# DSS_EDP0_V2A_CORE_VP_REGS_APB register map
Vendor: Texas Instruments
Peripheral module from a debugger description file (folder J721S2).
Registers are 32-bit, access not given, reset 0x0 unless marked. A register's access mark holds for its fields unless they carry their own. Offsets are as the file gives them; lines under a group give offsets from that group; [hi:lo] are bit positions; {n}, {i} and the like mark numbered series; 'fields as' and 'values as' point back to an identical list; <NAME> marks a mode.

## DSS_EDP0_V2A_CORE_VP_REGS_APB (part 1 of 4)
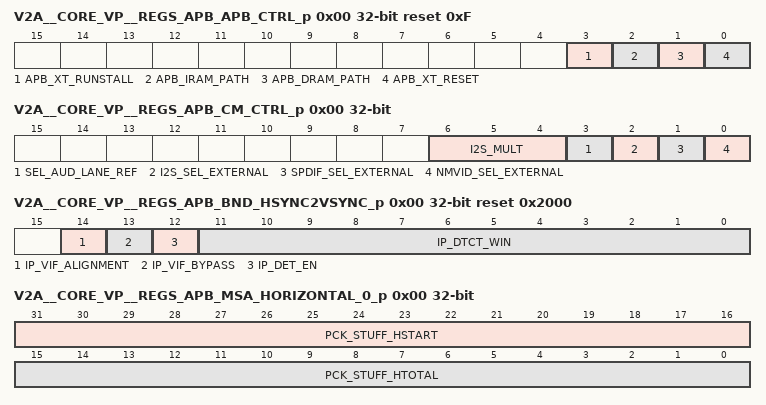
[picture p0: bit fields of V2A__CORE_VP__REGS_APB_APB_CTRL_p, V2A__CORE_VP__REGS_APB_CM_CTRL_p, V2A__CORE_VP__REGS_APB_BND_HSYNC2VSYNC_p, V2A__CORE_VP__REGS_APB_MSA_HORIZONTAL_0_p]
0x00 V2A__CORE_VP__REGS_APB_APB_CTRL_p reset 0xF — APB main control register
  [3] APB_XT_RUNSTALL rw — When 1 stalls the CPU from executing further instructions. This bit must be set HIGH during firmware load.
  [2] APB_IRAM_PATH rw — Unused. Kept RW for software backward compatibility.
  [1] APB_DRAM_PATH rw — Unused. Kept RW for software backward compatibility.
  [0] APB_XT_RESET rw — Internal uCPU reset. Active High. Must be cleared to enable firmware load and normal operation of the uCPU.
0x00 V2A__CORE_VP__REGS_APB_CM_CTRL_p — Clock Meter control
  [6:4] I2S_MULT rw — Select the division of N value for different I2S TDM configuration
  [3] SEL_AUD_LANE_REF rw — When 1 Select Audio CLK as a reference [HDMI] When 0 Select LANE CLK as a reference [DP]
  [2] I2S_SEL_EXTERNAL rw — When 1 Select external values of NMAUD [N/A] for I2S
  [1] SPDIF_SEL_EXTERNAL rw — When 1 Select external values of NMAUD [N/A] for SPDIF
  [0] NMVID_SEL_EXTERNAL rw — When 1 Select external values of NMVID [N/A]
0x00 V2A__CORE_VP__REGS_APB_CM_CTRL_p — Clock Meter control
  fields as V2A__CORE_VP__REGS_APB_CM_CTRL_p
0x00 V2A__CORE_VP__REGS_APB_BND_HSYNC2VSYNC_p reset 0x2000 — Video Input Interface Setting Register
  [14] IP_VIF_ALIGNMENT rw — Alignment of the input pixel data at the pixel interface: 0-MSB alignment 1-LSB alignment.
  [13] IP_VIF_BYPASS rw — Bypass video interface.
  [12] IP_DET_EN rw — Enable detection of Interlace formats after decided if the polarity is Automatic or Manual detection.
  [11:0] IP_DTCT_WIN rw — Bound for HSYNC to VSYNC for all fields.
0x00 V2A__CORE_VP__REGS_APB_MSA_HORIZONTAL_0_p rw — MSA horizontal parameters. This settings define MSA content (not used for input video stream parameters). This field must be set prior video is enabled and must not be changed when video transmission is active.
  [31:16] PCK_STUFF_HSTART — MSA Hstart value. Horizontal active start from leading edge of Hsync, measured in pixel count.
  [15:0] PCK_STUFF_HTOTAL — MSA HTotal value. Horizontal total of transmitted main video stream, measured in pixel count.
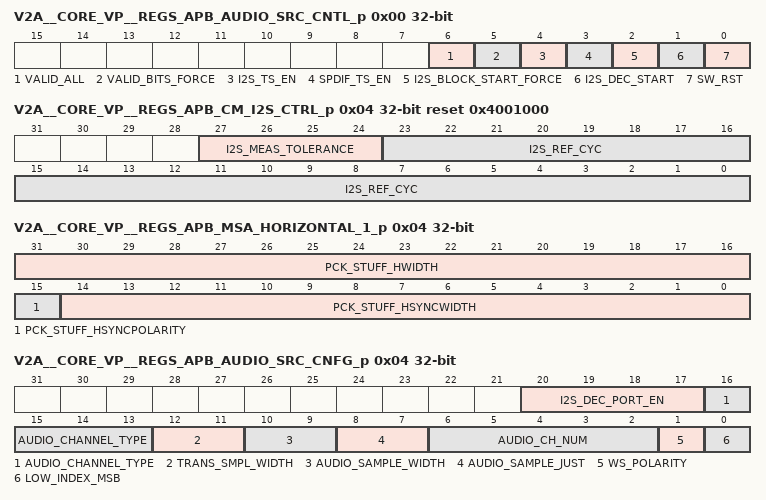
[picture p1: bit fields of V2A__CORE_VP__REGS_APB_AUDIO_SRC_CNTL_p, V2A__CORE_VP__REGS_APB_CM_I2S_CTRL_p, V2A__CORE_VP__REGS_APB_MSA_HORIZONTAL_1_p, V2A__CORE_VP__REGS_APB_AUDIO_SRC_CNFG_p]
0x00 V2A__CORE_VP__REGS_APB_AUDIO_SRC_CNTL_p — Audio source control
  [6] VALID_ALL rw — valid bit for all samples
  [5] VALID_BITS_FORCE rw — Force valid bits of the channels
  [4] I2S_TS_EN rw — Enable I2S Time Stamp when decoders are disabled
  [3] SPDIF_TS_EN rw — Enable SPDIF Time Stamp when decoders are disabled
  [2] I2S_BLOCK_START_FORCE rw — Force a Block Start in the audio stream
  [1] I2S_DEC_START rw — When high Source Decoder starts.
  [0] SW_RST rw — Software reset. Active high.
0x00 V2A__CORE_VP__REGS_APB_SOURCE_PIF_WR_ADDR_p — 4 MSB of the packet memory address in which the data is written.
  [3:0] WR_ADDR rw
0x04 V2A__CORE_VP__REGS_APB_xt_int_ctrl_p — Inernal CPU Interrupt Polarity Control Register.
  [1:0] XT_INT_POLARITY rw — Each bit inverts appropriate interrupt signal provided do internal CPU interrupt input.
0x04 V2A__CORE_VP__REGS_APB_CM_I2S_CTRL_p reset 0x4001000 — I2S clock control
  [27:24] I2S_MEAS_TOLERANCE rw — Measurement tolerance of Audio clock to be stable in clocks
  [23:0] I2S_REF_CYC rw — Reference cycles for I2S Audio meter
0x04 V2A__CORE_VP__REGS_APB_HSYNC2VSYNC_F1_L1_p — Status of HSYNC to VSYNC Distance Counter 1.
  [15:0] IP_DTCT_HSYNC2VSYNC_F1 ro — Value of HSYNC to VSYNC field 1.
0x04 V2A__CORE_VP__REGS_APB_MSA_HORIZONTAL_1_p rw — MSA horizontal parameters. This settings define MSA content (not used for input video stream parameters). This field must be set prior video is enabled and must not be changed when video transmission is active.
  [31:16] PCK_STUFF_HWIDTH — MSA Hwidth parameter. Active video width, measured in pixel count.
  [15] PCK_STUFF_HSYNCPOLARITY — MSA HSync Polarity. 0 - Active high pulse. Synchronization signal is high for the sync pulse width. 1 - Active low pulse. Synchronization signal is low for the sync pulse width. This value may be different than actual polarity of the stream received at the video input interface.
  [14:0] PCK_STUFF_HSYNCWIDTH — MSA HSyncWidth parameter. Hsync width, measured in pixel count.
0x04 V2A__CORE_VP__REGS_APB_AUDIO_SRC_CNFG_p — Audio source configuration
  [20:17] I2S_DEC_PORT_EN rw — Enables the I2S Decoder ports. Allowed values are: 0001 - I2S port 0 is enabled. 0011 - I2S ports 0,1 are enabled. 1111 - I2S ports 0,1,2,3 are enabled. No other values are allowed.
  [16:13] AUDIO_CHANNEL_TYPE rw — Set the transmission type.
  [12:11] TRANS_SMPL_WIDTH rw — Decoder Word Select width: 00-16 bit 01-24 bit 10-32 bit
  [10:9] AUDIO_SAMPLE_WIDTH rw — Decoder sample width: 00-16 bit 01-24 bit 10-32 bit
  [8:7] AUDIO_SAMPLE_JUST rw — Data justification setting: 00 left-justified 01 right-justified
  [6:2] AUDIO_CH_NUM rw — Number of channels to decode
  [1] WS_POLARITY rw — Word Select Polarity. 0: No change 1: Inverted.
  [0] LOW_INDEX_MSB rw — When low MSB is transmitted first. When high LSB is transmitted first.
0x04 V2A__CORE_VP__REGS_APB_SOURCE_PIF_WR_REQ_p — Write request bit for the host write transaction.
  [0] HOST_WR rw — Write request bit for the host write transaction, active high. Bit is automatically cleared when operation is completed.
0x08 V2A__CORE_VP__REGS_APB_MAILBOX_FULL_ADDR_p — Mailbox full indication status register. This register provides a status of the mailbox that is used to send messages from the Host processor to internal uCPU. Mailbox full flag can be a source of mailbox interrupt.
  [0] MAILBOX_FULL ro — Mailbox full indication. 0x1-mailbox full. No more messages can be sent to mailbox 0x0-mailbox not-full. At least 1 write can be performed to mailbox
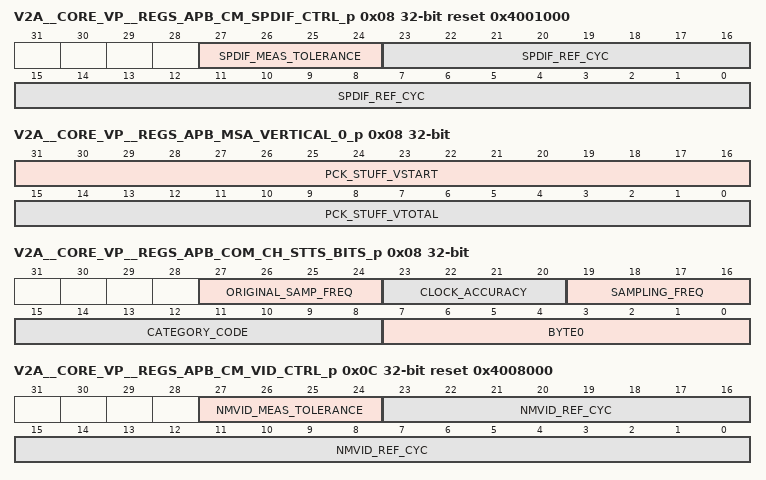
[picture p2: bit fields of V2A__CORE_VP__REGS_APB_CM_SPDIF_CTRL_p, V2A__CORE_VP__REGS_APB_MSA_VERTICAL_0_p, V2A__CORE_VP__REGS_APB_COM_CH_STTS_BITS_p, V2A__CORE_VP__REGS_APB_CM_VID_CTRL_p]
0x08 V2A__CORE_VP__REGS_APB_CM_SPDIF_CTRL_p reset 0x4001000 — SPDIF clock control
  [27:24] SPDIF_MEAS_TOLERANCE rw — SPDIF measurement tolerance to be stable in clocks
  [23:0] SPDIF_REF_CYC rw — Reference cycles of SPDIF measurement
0x08 V2A__CORE_VP__REGS_APB_HSYNC2VSYNC_F2_L1_p — Status of HSYNC to VSYNC Distance Counter 2
  [15:0] IP_DTCT_HSYNC2VSYNC_F2 ro — Value of HSYNC to VSYNC field 2.
0x08 V2A__CORE_VP__REGS_APB_MSA_VERTICAL_0_p rw — MSA vertical parameters. This settings define MSA content (not used for input video stream parameters). This field must be set prior video is enabled and must not be changed when video transmission is active.
  [31:16] PCK_STUFF_VSTART — MSA Vstart parameter. Vertical active start from leading edge of Vsync, measured in line count.
  [15:0] PCK_STUFF_VTOTAL — MSA Vtotal parameter. Vertical total of transmitted main video stream, measured in line count.
0x08 V2A__CORE_VP__REGS_APB_COM_CH_STTS_BITS_p — Common channels configuration
  [27:24] ORIGINAL_SAMP_FREQ rw — Original Sampling Freq. of transmitted channel. Same for all channels.
  [23:20] CLOCK_ACCURACY rw — Clock Accuracy of transmitted channel. Same for all channels.
  [19:16] SAMPLING_FREQ rw — Sampling Frequency of transmitted channel. Same for all channels.
  [15:8] CATEGORY_CODE rw — Category Code of transmitted channel. Same for all channels.
  [7:0] BYTE0 rw — Byte 0 of transmitted channel. Same for all channels.
0x08 V2A__CORE_VP__REGS_APB_SOURCE_PIF_RD_ADDR_p — 4 MSB of the packet memory address from which the data is read.
  [3:0] RD_ADDR rw
0x0C V2A__CORE_VP__REGS_APB_MAILBOX_EMPTY_ADDR_p reset 0x1 — Mailbox empty indication status register. This register provides a status of the mailbox that is used to send responses from the internal uCPU to host processor as a result of previously sent message. Mailbox empty flag can be a source of not-empty mailbox interrupt.
  [0] MAILBOX_EMPTY ro — Mailbox empty indication. 0x1-mailbox empty. No response available 0x0-mailbox not-empty. There is at least 1 byte of a response in mailbox available to read by Host processor
0x0C V2A__CORE_VP__REGS_APB_CM_VID_CTRL_p reset 0x4008000 — Video clock control
  [27:24] NMVID_MEAS_TOLERANCE rw — Video measurement tolerance in pixel clock cycles
  [23:0] NMVID_REF_CYC rw — Video Reference cycles
0x0C V2A__CORE_VP__REGS_APB_CM_VID_CTRL_p reset 0x4008000 — Video clock control
  fields as V2A__CORE_VP__REGS_APB_CM_VID_CTRL_p
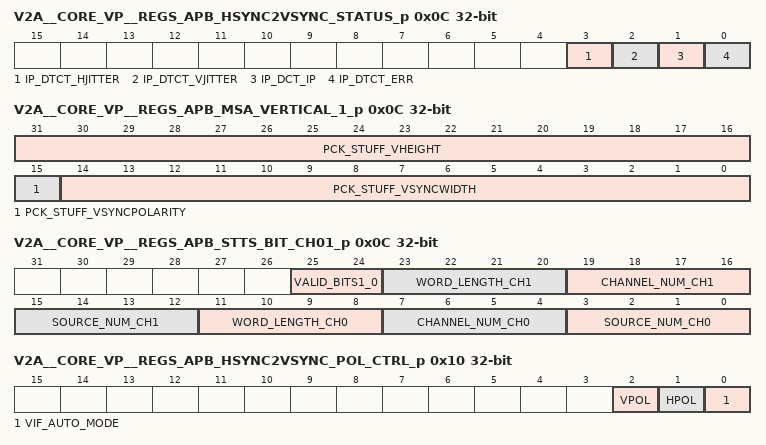
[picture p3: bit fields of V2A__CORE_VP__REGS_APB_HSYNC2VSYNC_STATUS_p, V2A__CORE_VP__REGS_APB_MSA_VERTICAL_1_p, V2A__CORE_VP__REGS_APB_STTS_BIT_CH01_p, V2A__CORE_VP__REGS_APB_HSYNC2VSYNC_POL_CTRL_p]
0x0C V2A__CORE_VP__REGS_APB_HSYNC2VSYNC_STATUS_p — Video Interface Status Register
  [3] IP_DTCT_HJITTER ro — Asserted when jitter is observed on htotal i.e. HSYNC rising edge to next HSYNC rising edge delay count. Clear on Read.
  [2] IP_DTCT_VJITTER ro — Asserted when jitter is observed on vtotal i.e. VSYNC rising edge to next VSYNC rising edge delay count. Clear on Read.
  [1] IP_DCT_IP ro — When asserted interlaced format is detected else progressive format.
  [0] IP_DTCT_ERR ro — Asserted when HSYNC to VSYNC bound is violated. Clear on Read.
0x0C V2A__CORE_VP__REGS_APB_MSA_VERTICAL_1_p rw — MSA vertical parameters. This settings define MSA content (not used for input video stream parameters). This field must be set prior video is enabled and must not be changed when video transmission is active.
  [31:16] PCK_STUFF_VHEIGHT — MSA VHeigh parameter. Active video height, measured in line count.
  [15] PCK_STUFF_VSYNCPOLARITY — MSA VSyncPolarity. 0 - Active high pulse. Synchronization signal is high for the sync pulse width. 1 - Active low pulse. Synchronization signal is low for the sync pulse width. This value may be different than actual polarity of the stream received at the video input interface.
  [14:0] PCK_STUFF_VSYNCWIDTH — MSA VSyncWidth parameter. Vsync width, measured in line count.
0x0C V2A__CORE_VP__REGS_APB_STTS_BIT_CH01_p — Channels 0,1 configuration
  [25:24] VALID_BITS1_0 rw — Valid Bits for channel 1 and 0 if force is enabled
  [23:20] WORD_LENGTH_CH1 rw — Channel 1 word length.
  [19:16] CHANNEL_NUM_CH1 rw — Channel 1 channel number.
  [15:12] SOURCE_NUM_CH1 rw — Channel 1 Source number.
  [11:8] WORD_LENGTH_CH0 rw — Channel 0 word length.
  [7:4] CHANNEL_NUM_CH0 rw — Channel 0 channel number.
  [3:0] SOURCE_NUM_CH0 rw — Channel 0 Source number.
0x0C V2A__CORE_VP__REGS_APB_SOURCE_PIF_RD_REQ_p — Read request bit for the host read transaction.
  [0] HOST_RD rw — Read request bit for the host read transaction, active high. Bit is automatically cleared when operation is completed.
0x10 V2A__CORE_VP__REGS_APB_mailbox0_wr_data_p — Mailbox write data register.
  [7:0] MAILBOX0_WR_DATA rw — Mailbox write data.
0x10 V2A__CORE_VP__REGS_APB_CM_LANE_CTRL_p — Lane control
  [23:0] LANE_REF_CYC rw — Reference cycles when using lane clock as Reference [DP]
0x10 V2A__CORE_VP__REGS_APB_HSYNC2VSYNC_POL_CTRL_p — Setting Polarity of HSYNC and VSYNC
  [2] VPOL rw — VSYNC polarity: 0-active HIGH 1-active LOW.
  [1] HPOL rw — HSYNC polarity: 0-active HIGH 1-active LOW.
  [0] VIF_AUTO_MODE rw — Automatic or Manual configuration of the polarity: 0-vpol and hpol settings are used 1-automatic detection of polarity of input VSYNC and HSYNC
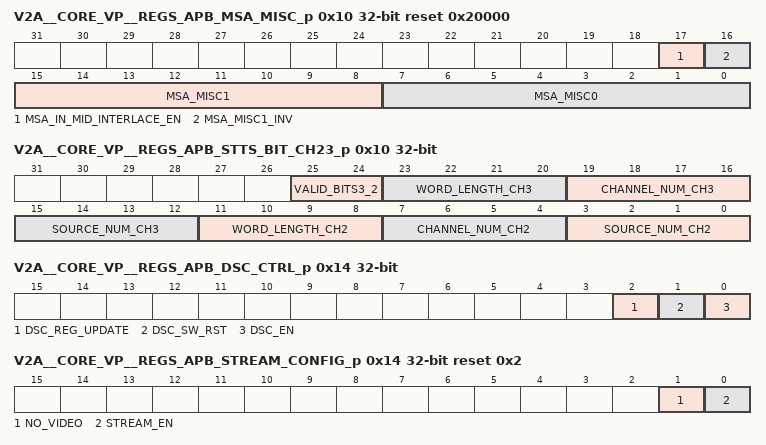
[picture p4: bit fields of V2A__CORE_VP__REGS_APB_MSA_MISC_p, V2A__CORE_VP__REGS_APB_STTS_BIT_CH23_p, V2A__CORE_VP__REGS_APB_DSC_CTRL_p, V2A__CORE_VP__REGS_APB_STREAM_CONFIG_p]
0x10 V2A__CORE_VP__REGS_APB_MSA_MISC_p reset 0x20000 — MSA MISC0 and MISC1 control register. This field must be set prior video is enabled and must not be changed when video transmission is active.
  [17] MSA_IN_MID_INTERLACE_EN rw — MSA transmission control in interlaced mode. 0 - enable transmission of MSA on each field, 1 - MSA transmitted on Top only
  [16] MSA_MISC1_INV rw — L/R toggle for interlaced and field sequential video. 0 - left 1 - right
  [15:8] MSA_MISC1 rw — MAS Miscellaneous1 as described in DisplayPort specification.
  [7:0] MSA_MISC0 rw — MSA Miscellaneous0 as described in DisplayPort specification.
0x10 V2A__CORE_VP__REGS_APB_STTS_BIT_CH23_p — Channels 2,3 configuration
  [25:24] VALID_BITS3_2 rw — Valid Bits for channel 3 and 2 if force is enabled
  [23:20] WORD_LENGTH_CH3 rw — Channel 3 word length.
  [19:16] CHANNEL_NUM_CH3 rw — Channel 3 channel number.
  [15:12] SOURCE_NUM_CH3 rw — Channel 3 Source number.
  [11:8] WORD_LENGTH_CH2 rw — Channel 2 word length.
  [7:4] CHANNEL_NUM_CH2 rw — Channel 2 channel number.
  [3:0] SOURCE_NUM_CH2 rw — Channel 2 Source number.
0x10 V2A__CORE_VP__REGS_APB_SOURCE_PIF_DATA_WR_p rw — The 32 bits of the data to be written to the packet memory.
  [31:0] DATA_WR — The 32 bits of the data to be written to the packet memory. When written to this register fifo1_wr_enable will automatically be asserted and the data is stored in FIFO.
0x14 V2A__CORE_VP__REGS_APB_mailbox0_rd_data_p — Mailbox Read data register.
  [7:0] MAILBOX0_RD_DATA ro — Mailbox Read data.
0x14 V2A__CORE_VP__REGS_APB_I2S_NM_STABLE_p — I2S clock stable, audio clock measured
  [0] I2S_MNAUD_STABLE ro — I2S NMAUD Mesurment stable
0x14 V2A__CORE_VP__REGS_APB_DSC_CTRL_p — DSC Setting Register
  [2] DSC_REG_UPDATE rw — DSC registers update: active HIGH.
  [1] DSC_SW_RST rw — DSC software reset: active HIGH.
  [0] DSC_EN rw — DSC enable bit: 1-DSC is enabled 0-DSC is disabled
0x14 V2A__CORE_VP__REGS_APB_STREAM_CONFIG_p reset 0x2 — Stream configuration register. Used only in MST mode.
  [1] NO_VIDEO rw — Stream no video mode. 0 - video mode 1 - no video mode
  [0] STREAM_EN rw — Stream enable. 0 - stream disabled 1 - stream enabled
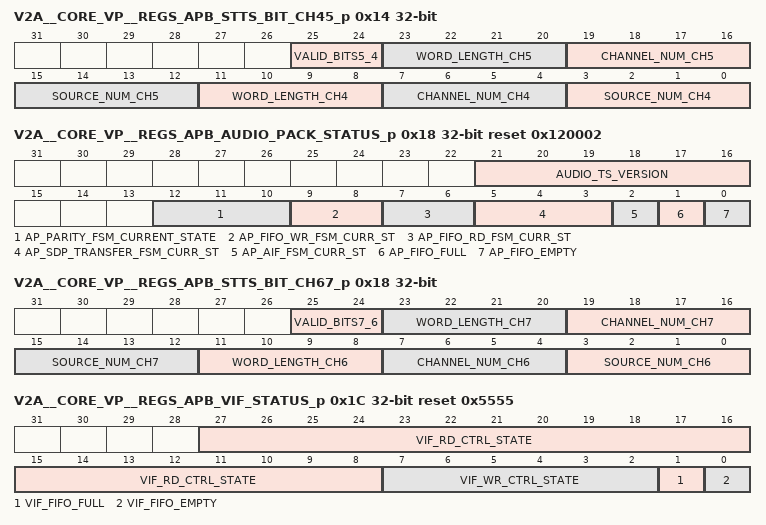
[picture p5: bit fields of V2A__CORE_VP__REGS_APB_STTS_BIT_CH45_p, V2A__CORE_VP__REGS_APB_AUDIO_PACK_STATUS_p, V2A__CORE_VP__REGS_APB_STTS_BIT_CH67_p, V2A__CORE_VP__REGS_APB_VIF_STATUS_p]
0x14 V2A__CORE_VP__REGS_APB_STTS_BIT_CH45_p — Channels 4,5 configuration
  [25:24] VALID_BITS5_4 rw — Valid Bits for channel 5 and 4 if force is enabled
  [23:20] WORD_LENGTH_CH5 rw — Channel 5 word length.
  [19:16] CHANNEL_NUM_CH5 rw — Channel 5 channel number.
  [15:12] SOURCE_NUM_CH5 rw — Channel 5 Source number.
  [11:8] WORD_LENGTH_CH4 rw — Channel 4 word length.
  [7:4] CHANNEL_NUM_CH4 rw — Channel 4 channel number.
  [3:0] SOURCE_NUM_CH4 rw — Channel 4 Source number.
0x14 V2A__CORE_VP__REGS_APB_SOURCE_PIF_DATA_RD_p ro — The 32 bits of the data to be read from the packet memory.
  [31:0] FIFO2_DATA_OUT — The 32 bits of the data to be read from the packet memory. When read from this register fifo2_rd_enable will automatically be asserted and the data is read from the FIFO.
0x18 V2A__CORE_VP__REGS_APB_KEEP_ALIVE_p — Software keep alive counter.
  [7:0] KEEP_ALIVE_CNT ro — Software keep alive counter. Counter is initialized to 0x0 after reset and incremented by 0x1 with every FW kernel loop. It can be used to determine if internal CPU started running correctly.
0x18 V2A__CORE_VP__REGS_APB_I2S_NCTS_STABLE_p — I2S clock stable, lane clock measured
  [0] I2S_NCTS_STABLE ro — i2s CTS measurement stable
0x18 V2A__CORE_VP__REGS_APB_AUDIO_PACK_STATUS_p reset 0x120002 — Status signals for the audio pack.
  [21:16] AUDIO_TS_VERSION rw — Audio timestamp version. This field is transmitted in HB3[7:2] of a Audio_TimeStamp SDP Header.
  [12:10] AP_PARITY_FSM_CURRENT_STATE ro — Audio pack parity calc fsm state. Used only for debug purposes.
  [9:8] AP_FIFO_WR_FSM_CURR_ST ro — Audio pack FIFO write fsm state. Used only for debug purposes.
  [7:6] AP_FIFO_RD_FSM_CURR_ST ro — Audio pack FIFO read fsm state. Used only for debug purposes.
  [5:3] AP_SDP_TRANSFER_FSM_CURR_ST ro — Audio pack sdp transfer fsm state. Used only for debug purposes.
  [2] AP_AIF_FSM_CURR_ST ro — Audio pack aif fsm state. Used only for debug purposes.
  [1] AP_FIFO_FULL ro — Audio Pack Sync FIFO full flag, active high. Used only for debug purposes.
  [0] AP_FIFO_EMPTY ro — Audio Pack Sync FIFO empty flag, active high. Used only for debug purposes.
0x18 V2A__CORE_VP__REGS_APB_STTS_BIT_CH67_p — Channels 6,7 configuration
  [25:24] VALID_BITS7_6 rw — Valid Bits for channel 7 and 6 if force is enabled
  [23:20] WORD_LENGTH_CH7 rw — Channel 7 word length.
  [19:16] CHANNEL_NUM_CH7 rw — Channel 7 channel number.
  [15:12] SOURCE_NUM_CH7 rw — Channel 7 Source number.
  [11:8] WORD_LENGTH_CH6 rw — Channel 6 word length.
  [7:4] CHANNEL_NUM_CH6 rw — Channel 6 channel number.
  [3:0] SOURCE_NUM_CH6 rw — Channel 6 Source number.
0x18 V2A__CORE_VP__REGS_APB_SOURCE_PIF_FIFO1_FLUSH_p — Fifo1 flush
  [0] FIFO1_FLUSH rw — Fifo1 flush bit, active high. Bit is automatically cleared when operation is completed.
0x1C V2A__CORE_VP__REGS_APB_VER_L_p — Software Version Register.
  [7:0] VER_LSB ro — Software Version lower byte. Loaded by Firmware at the beginning of firmware operation.
0x1C V2A__CORE_VP__REGS_APB_SPDIF_NM_STABLE_p — SPDIF clock stable, audio clock measured
  [0] SPDIF_MNAUD_STABLE ro — SPDIF NMAUD measurement stable
0x1C V2A__CORE_VP__REGS_APB_VIF_STATUS_p reset 0x5555 — Status signals for the VIF module. Used only for debug purposes.
  [27:8] VIF_RD_CTRL_STATE ro — VIF rd fsm current state.
  [7:2] VIF_WR_CTRL_STATE ro — VIF wr fsm current state.
  [1] VIF_FIFO_FULL ro — VIF ASync FIFO full flag, active high.
  [0] VIF_FIFO_EMPTY ro — VIF ASync FIFO empty flag, active high.
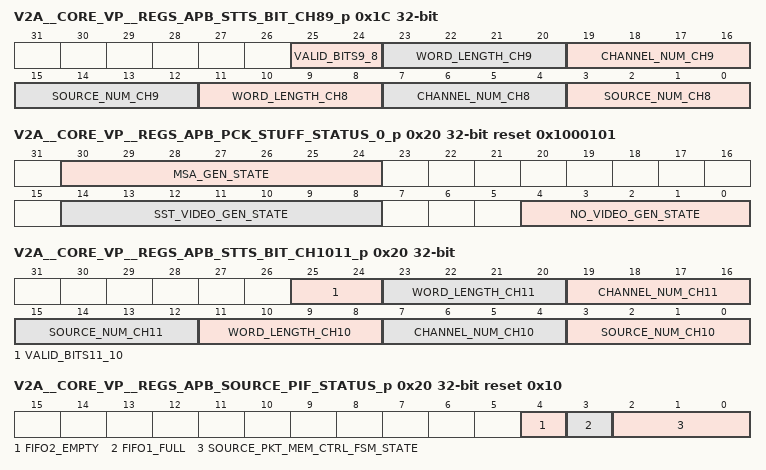
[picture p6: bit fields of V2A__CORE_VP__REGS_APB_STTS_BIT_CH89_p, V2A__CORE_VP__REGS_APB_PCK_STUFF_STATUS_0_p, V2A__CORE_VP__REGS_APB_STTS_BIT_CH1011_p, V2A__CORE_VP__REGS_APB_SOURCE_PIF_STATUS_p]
0x1C V2A__CORE_VP__REGS_APB_STTS_BIT_CH89_p — Channels 8,9 configuration
  [25:24] VALID_BITS9_8 rw — Valid Bits for channel 9 and 8 if force is enabled
  [23:20] WORD_LENGTH_CH9 rw — Channel 9 word length.
  [19:16] CHANNEL_NUM_CH9 rw — Channel 9 channel number.
  [15:12] SOURCE_NUM_CH9 rw — Channel 9 Source number.
  [11:8] WORD_LENGTH_CH8 rw — Channel 8 word length.
  [7:4] CHANNEL_NUM_CH8 rw — Channel 8 channel number.
  [3:0] SOURCE_NUM_CH8 rw — Channel 8 Source number.
0x1C V2A__CORE_VP__REGS_APB_SOURCE_PIF_FIFO2_FLUSH_p — Fifo2 flush
  [0] FIFO2_FLUSH rw — Fifo2 flush bit, active high. Bit is automatically cleared when operation is completed.
0x20 V2A__CORE_VP__REGS_APB_VER_H_p — Software Version Register.
  [7:0] VER_MSB ro — Software Version higher byte. Loaded by Firmware at the beginning of firmware operation.
0x20 V2A__CORE_VP__REGS_APB_SPDIF_NCTS_STABLE_p — SPDIF clock stable, lane clock measured
  [0] SPDIF_NCTS_STABLE ro — SPDIF CTS measurement stable
0x20 V2A__CORE_VP__REGS_APB_PCK_STUFF_STATUS_0_p reset 0x1000101 — Status of the the video stuff module (0). Used only for debug purposes.
  [30:24] MSA_GEN_STATE ro — Secondary Data generator FSM status.
  [14:8] SST_VIDEO_GEN_STATE ro — SST video generator FSM status.
  [4:0] NO_VIDEO_GEN_STATE ro — No video generator FSM status.
0x20 V2A__CORE_VP__REGS_APB_STTS_BIT_CH1011_p — Channels 10,11 configuration
  [25:24] VALID_BITS11_10 rw — Valid Bits for channel 11 and 10 if force is enabled
  [23:20] WORD_LENGTH_CH11 rw — Channel 11 word length.
  [19:16] CHANNEL_NUM_CH11 rw — Channel 11 channel number.
  [15:12] SOURCE_NUM_CH11 rw — Channel 11 Source number.
  [11:8] WORD_LENGTH_CH10 rw — Channel 10 word length.
  [7:4] CHANNEL_NUM_CH10 rw — Channel 10 channel number.
  [3:0] SOURCE_NUM_CH10 rw — Channel 10 Source number.
0x20 V2A__CORE_VP__REGS_APB_SOURCE_PIF_STATUS_p reset 0x10 — Status bits for the PIF module
  [4] FIFO2_EMPTY ro — Fifo2 empty indication, when high indicates that FIFO2 is empty
  [3] FIFO1_FULL ro — Fifo1 full indication, when high indicates that FIFO1 is full
  [2:0] SOURCE_PKT_MEM_CTRL_FSM_STATE ro — State of the FSM that controls packet memory transactions.
0x24 V2A__CORE_VP__REGS_APB_VER_LIB_L_ADDR_p — Software Library Version Register.
  [7:0] SW_LIB_VER_L ro — Software Library Version lower byte. Loaded by Firmware at the beginning of firmware operation.
0x24 V2A__CORE_VP__REGS_APB_NMVID_MEAS_STABLE_p — Video clock stable
  [0] ST_NMVID_MEAS_STABLE ro — Pixel clock NMVID measurement stable
0x24 V2A__CORE_VP__REGS_APB_NMVID_MEAS_STABLE_p — Video clock stable
  [0] ST_NMVID_MEAS_STABLE ro — Pixel clock NMVID measurement stable
0x24 V2A__CORE_VP__REGS_APB_PCK_STUFF_STATUS_1_p reset 0x1 — Status of the the video stuff module (1). Used only for debug purposes.
  [5:0] SST_SS_GEN_STATE ro — MSA generator FSM status.
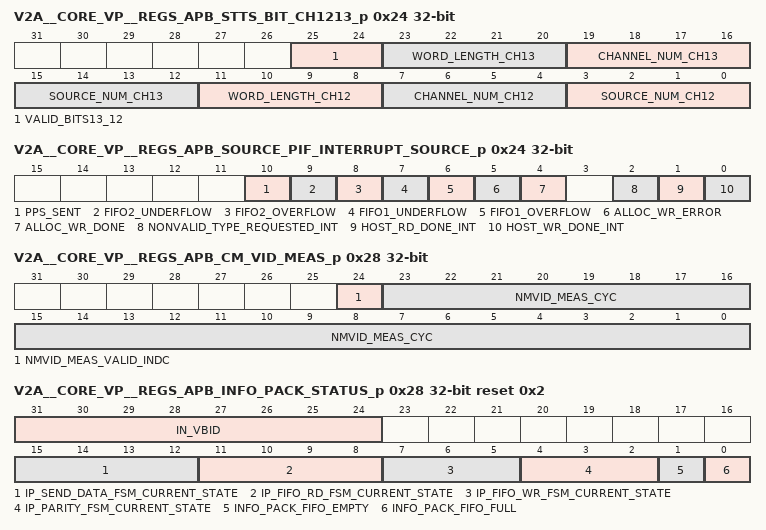
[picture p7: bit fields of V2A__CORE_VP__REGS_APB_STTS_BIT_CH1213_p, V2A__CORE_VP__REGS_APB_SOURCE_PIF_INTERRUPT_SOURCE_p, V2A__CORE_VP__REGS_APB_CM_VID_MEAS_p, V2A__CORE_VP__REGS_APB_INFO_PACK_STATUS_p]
0x24 V2A__CORE_VP__REGS_APB_STTS_BIT_CH1213_p — Channels 12,13 configuration
  [25:24] VALID_BITS13_12 rw — Valid Bits for channel 13 and 12 if force is enabled
  [23:20] WORD_LENGTH_CH13 rw — Channel 13 word length.
  [19:16] CHANNEL_NUM_CH13 rw — Channel 13 channel number.
  [15:12] SOURCE_NUM_CH13 rw — Channel 13 Source number.
  [11:8] WORD_LENGTH_CH12 rw — Channel 12 word length.
  [7:4] CHANNEL_NUM_CH12 rw — Channel 12 channel number.
  [3:0] SOURCE_NUM_CH12 rw — Channel 12 Source number.
0x24 V2A__CORE_VP__REGS_APB_SOURCE_PIF_INTERRUPT_SOURCE_p — Interrupt sources of the PIF module, active high. Automatically cleared on read. If any of this interrupt is enabled and triggered bit apb_pif_intr_status in APB_INT_STATUS register is set.
  [10] PPS_SENT ro — PPS sent to framer indication. Active HIGH. Clear on read.
  [9] FIFO2_UNDERFLOW ro — Fifo2 underflow indication. Indicates incorrect programming sequence. Active HIGH. Clear on read.
  [8] FIFO2_OVERFLOW ro — Fifo2 overflow indication. Indicates incorrect programming sequence. Active HIGH. Clear on read.
  [7] FIFO1_UNDERFLOW ro — Fifo1 underflow indication. Indicates incorrect programming sequence. Active HIGH. Clear on read.
  [6] FIFO1_OVERFLOW ro — Fifo1 overflow indication. Indicates incorrect programming sequence. Active HIGH. Clear on read.
  [5] ALLOC_WR_ERROR ro — Error happened, invalid write to the allocation table. Indicates incorrect programming sequence. Active HIGH. Clear on read.
  [4] ALLOC_WR_DONE ro — Successful write to the allocation table. Active HIGH. Clear on read.
  [2] NONVALID_TYPE_REQUESTED_INT ro — Indication that nonvalid type of packet is requested by the packet interface. Indicates incorrect programming sequence. Active HIGH. Clear on read.
  [1] HOST_RD_DONE_INT ro — Indication that the host read transaction finished. Active HIGH. Clear on read.
  [0] HOST_WR_DONE_INT ro — Indication that the host write transaction finished. Active HIGH. Clear on read.
0x28 V2A__CORE_VP__REGS_APB_VER_LIB_H_ADDR_p — Software Library Version Register.
  [7:0] SW_LIB_VER_H ro — Software Library Version higher byte. Loaded by Firmware at the beginning of firmware operation.
0x28 V2A__CORE_VP__REGS_APB_CM_VID_MEAS_p — Video cycles measure
  [24] NMVID_MEAS_VALID_INDC rw — When Toggle Valid pulse is generated to sample MNVID fix value
  [23:0] NMVID_MEAS_CYC rw — Fixed Value for NVID , The MVID is nmvid_ref_cyc[23:0]
0x28 V2A__CORE_VP__REGS_APB_CM_VID_MEAS_p — Video cycles measure
  fields as V2A__CORE_VP__REGS_APB_CM_VID_MEAS_p
0x28 V2A__CORE_VP__REGS_APB_INFO_PACK_STATUS_p reset 0x2 — Status signals for the info pack module, as well as final VB-ID value. Used only for debug purposes.
  [31:24] IN_VBID ro — Value of the sent VB-ID [vb_id_final].
  [15:12] IP_SEND_DATA_FSM_CURRENT_STATE ro — State of the send_data FSM.
  [11:8] IP_FIFO_RD_FSM_CURRENT_STATE ro — State of the fifo_rd FSM.
  [7:5] IP_FIFO_WR_FSM_CURRENT_STATE ro — State of the fifo_wr FSM.
  [4:2] IP_PARITY_FSM_CURRENT_STATE ro — State of the parity FSM.
  [1] INFO_PACK_FIFO_EMPTY ro — Info_pack fifo empty flag, active high.
  [0] INFO_PACK_FIFO_FULL ro — Info_pack fifo full flag, active high.
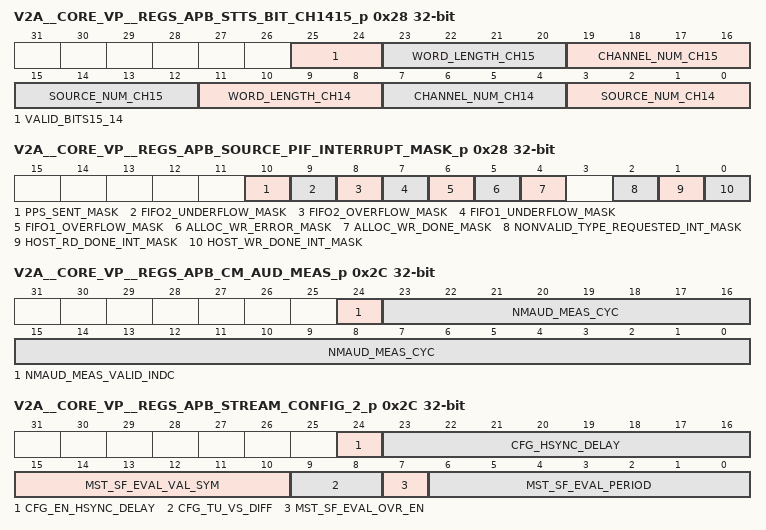
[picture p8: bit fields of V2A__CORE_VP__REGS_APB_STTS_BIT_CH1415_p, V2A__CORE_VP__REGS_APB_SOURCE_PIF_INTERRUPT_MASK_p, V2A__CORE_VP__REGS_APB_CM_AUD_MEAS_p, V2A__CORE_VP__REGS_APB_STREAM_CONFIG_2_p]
0x28 V2A__CORE_VP__REGS_APB_STTS_BIT_CH1415_p — Channels 14,15 configuration
  [25:24] VALID_BITS15_14 rw — Valid Bits for channel 15 and 14 if force is enabled
  [23:20] WORD_LENGTH_CH15 rw — Channel 15 word length.
  [19:16] CHANNEL_NUM_CH15 rw — Channel 15 channel number.
  [15:12] SOURCE_NUM_CH15 rw — Channel 15 Source number.
  [11:8] WORD_LENGTH_CH14 rw — Channel 14 word length.
  [7:4] CHANNEL_NUM_CH14 rw — Channel 14 channel number.
  [3:0] SOURCE_NUM_CH14 rw — Channel 14 Source number.
0x28 V2A__CORE_VP__REGS_APB_SOURCE_PIF_INTERRUPT_MASK_p — Masks for the interrupt sources in the SOURCE_PIF_INTERRUPT_SOURCE register, when set high, these bits disable the corresponding interrupts
  [10] PPS_SENT_MASK rw — Masks the pps_sent interrupt. 0x0-interrupt enabled 0x1-interrupt disabled
  [9] FIFO2_UNDERFLOW_MASK rw — Masks the fifo2_underflow interrupt. 0x0-interrupt enabled 0x1-interrupt disabled
  [8] FIFO2_OVERFLOW_MASK rw — Masks the fifo2_overflow interrupt. 0x0-interrupt enabled 0x1-interrupt disabled
  [7] FIFO1_UNDERFLOW_MASK rw — Masks the fifo1_underflow interrupt. 0x0-interrupt enabled 0x1-interrupt disabled
  [6] FIFO1_OVERFLOW_MASK rw — Masks the fifo1_overflow interrupt. 0x0-interrupt enabled 0x1-interrupt disabled
  [5] ALLOC_WR_ERROR_MASK rw — Masks the alloc_wr_error interrupt. 0x0-interrupt enabled 0x1-interrupt disabled
  [4] ALLOC_WR_DONE_MASK rw — Masks the alloc_wr_done interrupt. 0x0-interrupt enabled 0x1-interrupt disabled
  [2] NONVALID_TYPE_REQUESTED_INT_MASK rw — Masks the nonvalid_type_requested_int interrupt. 0x0-interrupt enabled 0x1-interrupt disabled
  [1] HOST_RD_DONE_INT_MASK rw — Masks the host_rd_done_int interrupt. 0x0-interrupt enabled 0x1-interrupt disabled
  [0] HOST_WR_DONE_INT_MASK rw — Masks the host_wr_done_int interrupt. 0x0-interrupt enabled 0x1-interrupt disabled
0x2C V2A__CORE_VP__REGS_APB_SW_DEBUG_L_p — Software/Firmware Debug Register.
  [7:0] SW_DEBUG_7_0 ro — Register used for debug purposes [lower byte]. Can be written internally by firmware to allow Core Driver to read the internal status. Not used during normal operation since it requires a special version of firmware with a debug capabilities.
0x2C V2A__CORE_VP__REGS_APB_CM_AUD_MEAS_p — Audio cycles measure
  [24] NMAUD_MEAS_VALID_INDC rw — When Toggle Valid pulse is generated to sample MNAUD fix value
  [23:0] NMAUD_MEAS_CYC rw — Fixed Value for NAUD, The MAUD is lane_ref_cyc[23:0]
0x2C V2A__CORE_VP__REGS_APB_STREAM_CONFIG_2_p — Additional video stream configuration. Used for debug purposes or for non-standard video formats.
  [24] CFG_EN_HSYNC_DELAY rw — Unused. Kept RW for software backward compatibility.
  [23:16] CFG_HSYNC_DELAY rw — Unused. Kept RW for software backward compatibility.
  [15:10] MST_SF_EVAL_VAL_SYM rw — Number of valid symbols to output during stream fill evaluation period. This should be less than mst_sf_eval_period.
  [9:8] CFG_TU_VS_DIFF rw — Unused. Kept RW for software backward compatibility.
  [7] MST_SF_EVAL_OVR_EN rw — Enable override of mst_sf_eval_period, mst_sf_eval_val_sym and cfg_tu_vs_diff when in MST mode.
  [6:0] MST_SF_EVAL_PERIOD rw — Stream fill evaluation period when in MST mode and mst_sf_eval_ovr_en bit is set.
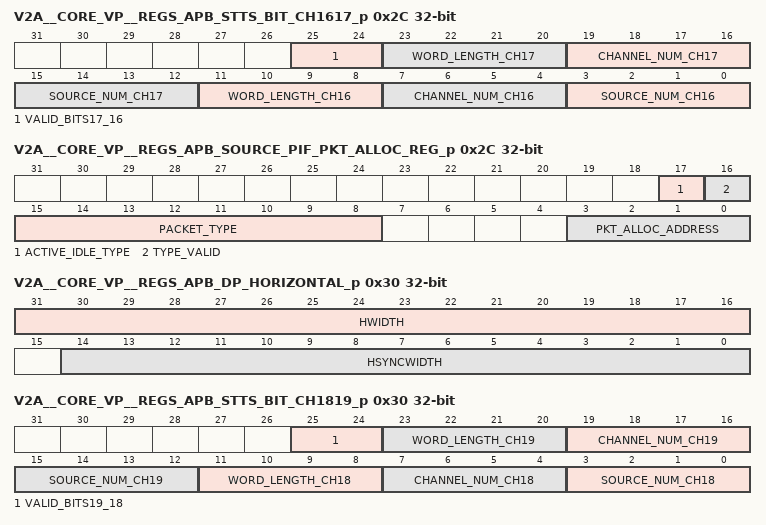
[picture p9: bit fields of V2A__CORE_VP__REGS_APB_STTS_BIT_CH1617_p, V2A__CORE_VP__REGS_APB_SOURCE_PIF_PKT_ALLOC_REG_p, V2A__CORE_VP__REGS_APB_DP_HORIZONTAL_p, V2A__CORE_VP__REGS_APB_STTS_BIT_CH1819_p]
0x2C V2A__CORE_VP__REGS_APB_STTS_BIT_CH1617_p — Channels 16,17 configuration
  [25:24] VALID_BITS17_16 rw — Valid Bits for channel 17 and 16 if force is enabled
  [23:20] WORD_LENGTH_CH17 rw — Channel 17 word length.
  [19:16] CHANNEL_NUM_CH17 rw — Channel 17 channel number.
  [15:12] SOURCE_NUM_CH17 rw — Channel 17 Source number.
  [11:8] WORD_LENGTH_CH16 rw — Channel 16 word length.
  [7:4] CHANNEL_NUM_CH16 rw — Channel 16 channel number.
  [3:0] SOURCE_NUM_CH16 rw — Channel 16 Source number.
0x2C V2A__CORE_VP__REGS_APB_SOURCE_PIF_PKT_ALLOC_REG_p — Packet configuration to be stored in the allocation table
  [17] ACTIVE_IDLE_TYPE rw — Indicates in which mode the SDP will be sent. 0- no_video mode, 1- video mode
  [16] TYPE_VALID rw — 1 for valid, 0 for nonvalid
  [15:8] PACKET_TYPE rw — 8-bit value of the packet type
  [3:0] PKT_ALLOC_ADDRESS rw — Address of the register in the source allocation table
0x30 V2A__CORE_VP__REGS_APB_SW_DEBUG_H_p — Software/Firmware Debug Register.
  [7:0] SW_DEBUG_15_8 ro — Register used for debug purposes [higher byte]. Can be written internally by firmware to allow Core Driver to read the internal status. Not used during normal operation since it requires a special version of firmware with a debug capabilities.
0x30 V2A__CORE_VP__REGS_APB_I2S_MEAS_p — I2S clock measurement HDMI
  [23:0] I2_MEAS ro — I2S measurement value
0x30 V2A__CORE_VP__REGS_APB_DP_HORIZONTAL_p — Video Horizontal parameters. This register must be programmed prior enabling video and must not be changed while video is being transmitted. In case of compressed stream transmission (DSC) and split panel mode values in this register must be divided by 2 since VIF interface operates at pixel clock divided by 2. This will ensure the same timing compared to uncompressed stream and.
  [31:16] HWIDTH rw — Horizontal Active Video Width. Width of video active period [VACTIVE] expressed in number pixel clock cycles. It must be a multiply of 16.
  [14:0] HSYNCWIDTH rw — Horizontal Sync Width. Width of horizontal synchronization pulse [HSYNC] expressed in number pixel clock cycles.
0x30 V2A__CORE_VP__REGS_APB_STTS_BIT_CH1819_p — Channels 18,19 configuration
  [25:24] VALID_BITS19_18 rw — Valid Bits for channel 19 and 18 if force is enabled
  [23:20] WORD_LENGTH_CH19 rw — Channel 19 word length.
  [19:16] CHANNEL_NUM_CH19 rw — Channel 19 channel number.
  [15:12] SOURCE_NUM_CH19 rw — Channel 19 Source number.
  [11:8] WORD_LENGTH_CH18 rw — Channel 18 word length.
  [7:4] CHANNEL_NUM_CH18 rw — Channel 18 channel number.
  [3:0] SOURCE_NUM_CH18 rw — Channel 18 Source number.
0x30 V2A__CORE_VP__REGS_APB_SOURCE_PIF_PKT_ALLOC_WR_EN_p — Enable bit for writing to the allocation table
  [0] PKT_ALLOC_WR_EN rw — Enable bit for writing to the allocation table, active high
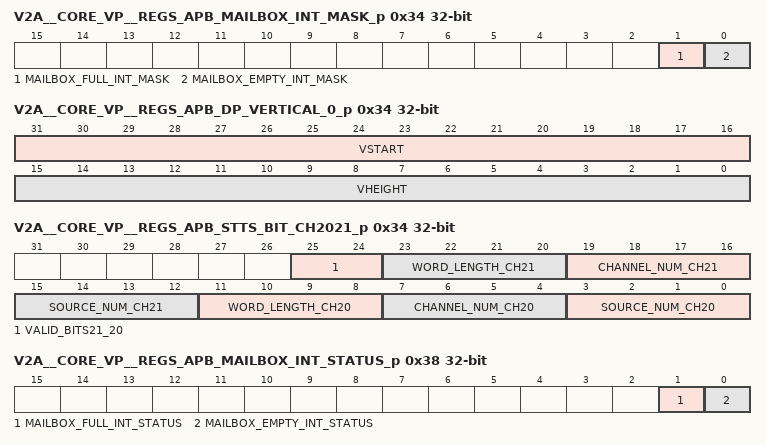
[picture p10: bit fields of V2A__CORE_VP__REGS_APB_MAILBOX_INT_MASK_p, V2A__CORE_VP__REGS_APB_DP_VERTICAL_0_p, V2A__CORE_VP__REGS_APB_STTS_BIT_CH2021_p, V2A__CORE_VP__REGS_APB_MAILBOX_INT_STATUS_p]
0x34 V2A__CORE_VP__REGS_APB_MAILBOX_INT_MASK_p — Mailbox Interrupt mask register.
  [1] MAILBOX_FULL_INT_MASK rw — Mailbox Full Interrupt mask 0x0-interrupt enabled 0x1-interrupt disabled
  [0] MAILBOX_EMPTY_INT_MASK rw — Mailbox Not-empty Interrupt mask 0x0-interrupt enabled 0x1-interrupt disabled
0x34 V2A__CORE_VP__REGS_APB_SPDIF_MEAS_p — SPDIF clock measurement HDMI
  [23:0] SPDIF_MEAS ro — SPDIF Clock Meter measurement value [in DP]
0x34 V2A__CORE_VP__REGS_APB_DP_VERTICAL_0_p rw — Video Vertical parameters. This register must be programmed prior enabling video and must not be changed while video is being transmitted.
  [31:16] VSTART — Vertical Active Start [VSTART]. Index of the first active line in a video frame.
  [15:0] VHEIGHT — Vertical Active High [VACTIVE]. Number of active lines in a video frame.
0x34 V2A__CORE_VP__REGS_APB_STTS_BIT_CH2021_p — Channels 20,21 configuration
  [25:24] VALID_BITS21_20 rw — Valid Bits for channel 21 and 20 if force is enabled
  [23:20] WORD_LENGTH_CH21 rw — Channel 21 word length.
  [19:16] CHANNEL_NUM_CH21 rw — Channel 21 channel number.
  [15:12] SOURCE_NUM_CH21 rw — Channel 21 Source number.
  [11:8] WORD_LENGTH_CH20 rw — Channel 20 word length.
  [7:4] CHANNEL_NUM_CH20 rw — Channel 20 channel number.
  [3:0] SOURCE_NUM_CH20 rw — Channel 20 Source number.
0x34 V2A__CORE_VP__REGS_APB_SOURCE_PIF_SW_RESET_p — Software reset.
  [0] SW_RST rw — Software reset, active high. Bit is automatically cleared when operation is completed.
0x38 V2A__CORE_VP__REGS_APB_MAILBOX_INT_STATUS_p — Mailbox Interrupt Status register.
  [1] MAILBOX_FULL_INT_STATUS ro — Mailbox full interrupt. Active HIGH. Cleared on read. This interrupt is set when mailbox becomes full which means there is no more space for messages sent from Host processor to internal uCPU and when this interrupt is enabled in MAILBOX_INT_MASK_p register. It is set when mailbox_full bit transitions from 0 to 1.
  [0] MAILBOX_EMPTY_INT_STATUS ro — Mailbox not-empty interrupt. Active HIGH. Cleared on read. This interrupt is set when mailbox becomes not-empty which means there is a response in the mailbox available to read by the Host processer and when interrupt is enabled in MAILBOX_INT_MASK_p register. It is set when mailbox_empty bit transitions from 1 to 0.
0x38 V2A__CORE_VP__REGS_APB_NMVID_MEAS_p — Video clock measurement
  [23:0] NMVID_MEAS ro — Video clock measurement value
0x38 V2A__CORE_VP__REGS_APB_NMVID_MEAS_p — Video clock measurement
  [23:0] NMVID_MEAS ro — Video clock measurement value
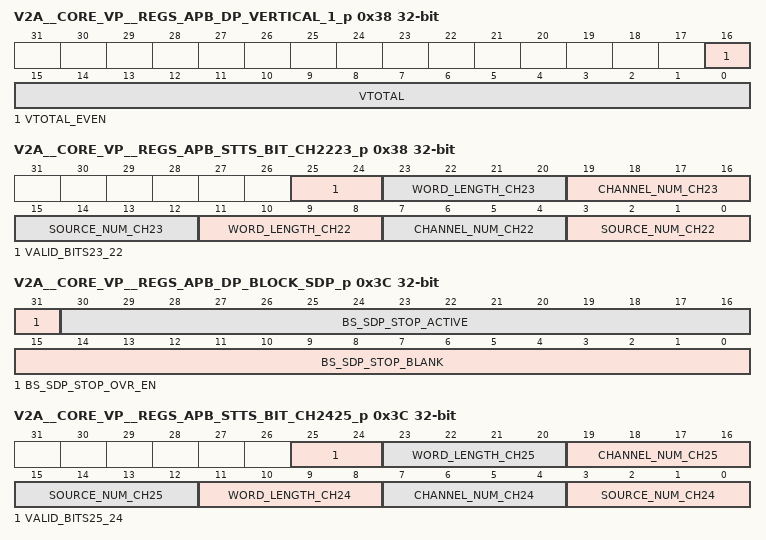
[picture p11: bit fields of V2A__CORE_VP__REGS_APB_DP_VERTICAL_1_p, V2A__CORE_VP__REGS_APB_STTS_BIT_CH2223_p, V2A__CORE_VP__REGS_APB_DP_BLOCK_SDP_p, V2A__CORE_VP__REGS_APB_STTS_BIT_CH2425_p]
0x38 V2A__CORE_VP__REGS_APB_DP_VERTICAL_1_p — Video Vertical parameters. This register must be programmed prior enabling video and must not be changed while video is being transmitted.
  [16] VTOTAL_EVEN rw — Indicate Vtotal is an even number as described in MISC1[0] in DisplayPort specification. Active high.
  [15:0] VTOTAL rw — Vertical Total Heigh [HTOTAL]. Total number of lines per frame.
0x38 V2A__CORE_VP__REGS_APB_STTS_BIT_CH2223_p — Channels 22,23 configuration
  [25:24] VALID_BITS23_22 rw — Valid Bits for channel 23 and 22 if force is enabled
  [23:20] WORD_LENGTH_CH23 rw — Channel 23 word length.
  [19:16] CHANNEL_NUM_CH23 rw — Channel 23 channel number.
  [15:12] SOURCE_NUM_CH23 rw — Channel 23 Source number.
  [11:8] WORD_LENGTH_CH22 rw — Channel 22 word length.
  [7:4] CHANNEL_NUM_CH22 rw — Channel 22 channel number.
  [3:0] SOURCE_NUM_CH22 rw — Channel 22 Source number.
0x38 V2A__CORE_VP__REGS_APB_SOURCE_PIF_PPS_HEADER_p rw — PPS header
  [31:0] PPS_HEADER — value of the PPS header as per DPv1.4
0x3C V2A__CORE_VP__REGS_APB_SW_CLK_L_p — Core Clock frequency
  [7:0] SW_CLOCK_VAL_L rw — Fractional of the clock decimal value. Should be loaded by API to the value that reflects the frequency of clock provided to core clock input.
0x3C V2A__CORE_VP__REGS_APB_DP_BLOCK_SDP_p rw — SDP scheduling control register. Allows for tuning when SDP can be sent during blanking periods. This register must be programmed prior enabling video and must not be changed while video is being transmitted.
  [31] BS_SDP_STOP_OVR_EN — Enable override settings. If this bit is not set, the hardware will not automatically block SDP transmission during video lines, this may result in shifting of video timing.
  [30:16] BS_SDP_STOP_ACTIVE — Block SDP scheduling after specified cycles after BS during horizontal blank lines. Maximum is 32767. If set to 0, no SDPs will be transmitted during hblank. Only used when bs_sdp_stop_ovr_en is set to 1.
  [15:0] BS_SDP_STOP_BLANK — Block SDP scheduling after specified cycles after BS during vertical blank lines. Maximum is 65535. If set to 0, no SDPs will be transmitted during vblank. Only used when bs_sdp_stop_ovr_en is set to 1.
0x3C V2A__CORE_VP__REGS_APB_STTS_BIT_CH2425_p — Channels 24,25 configuration
  [25:24] VALID_BITS25_24 rw — Valid Bits for channel 25 and 24 if force is enabled
  [23:20] WORD_LENGTH_CH25 rw — Channel 25 word length.
  [19:16] CHANNEL_NUM_CH25 rw — Channel 25 channel number.
  [15:12] SOURCE_NUM_CH25 rw — Channel 25 Source number.
  [11:8] WORD_LENGTH_CH24 rw — Channel 24 word length.
  [7:4] CHANNEL_NUM_CH24 rw — Channel 24 channel number.
  [3:0] SOURCE_NUM_CH24 rw — Channel 24 Source number.
0x3C V2A__CORE_VP__REGS_APB_SOURCE_PIF_PPS_p — PPS SDP indication
  [0] PPS rw — PPS SDP indication, active high. When set, the SDP to be read/written from/to the memory by the host is in fact PPS. Bit is automatically cleared when operation is completed.
